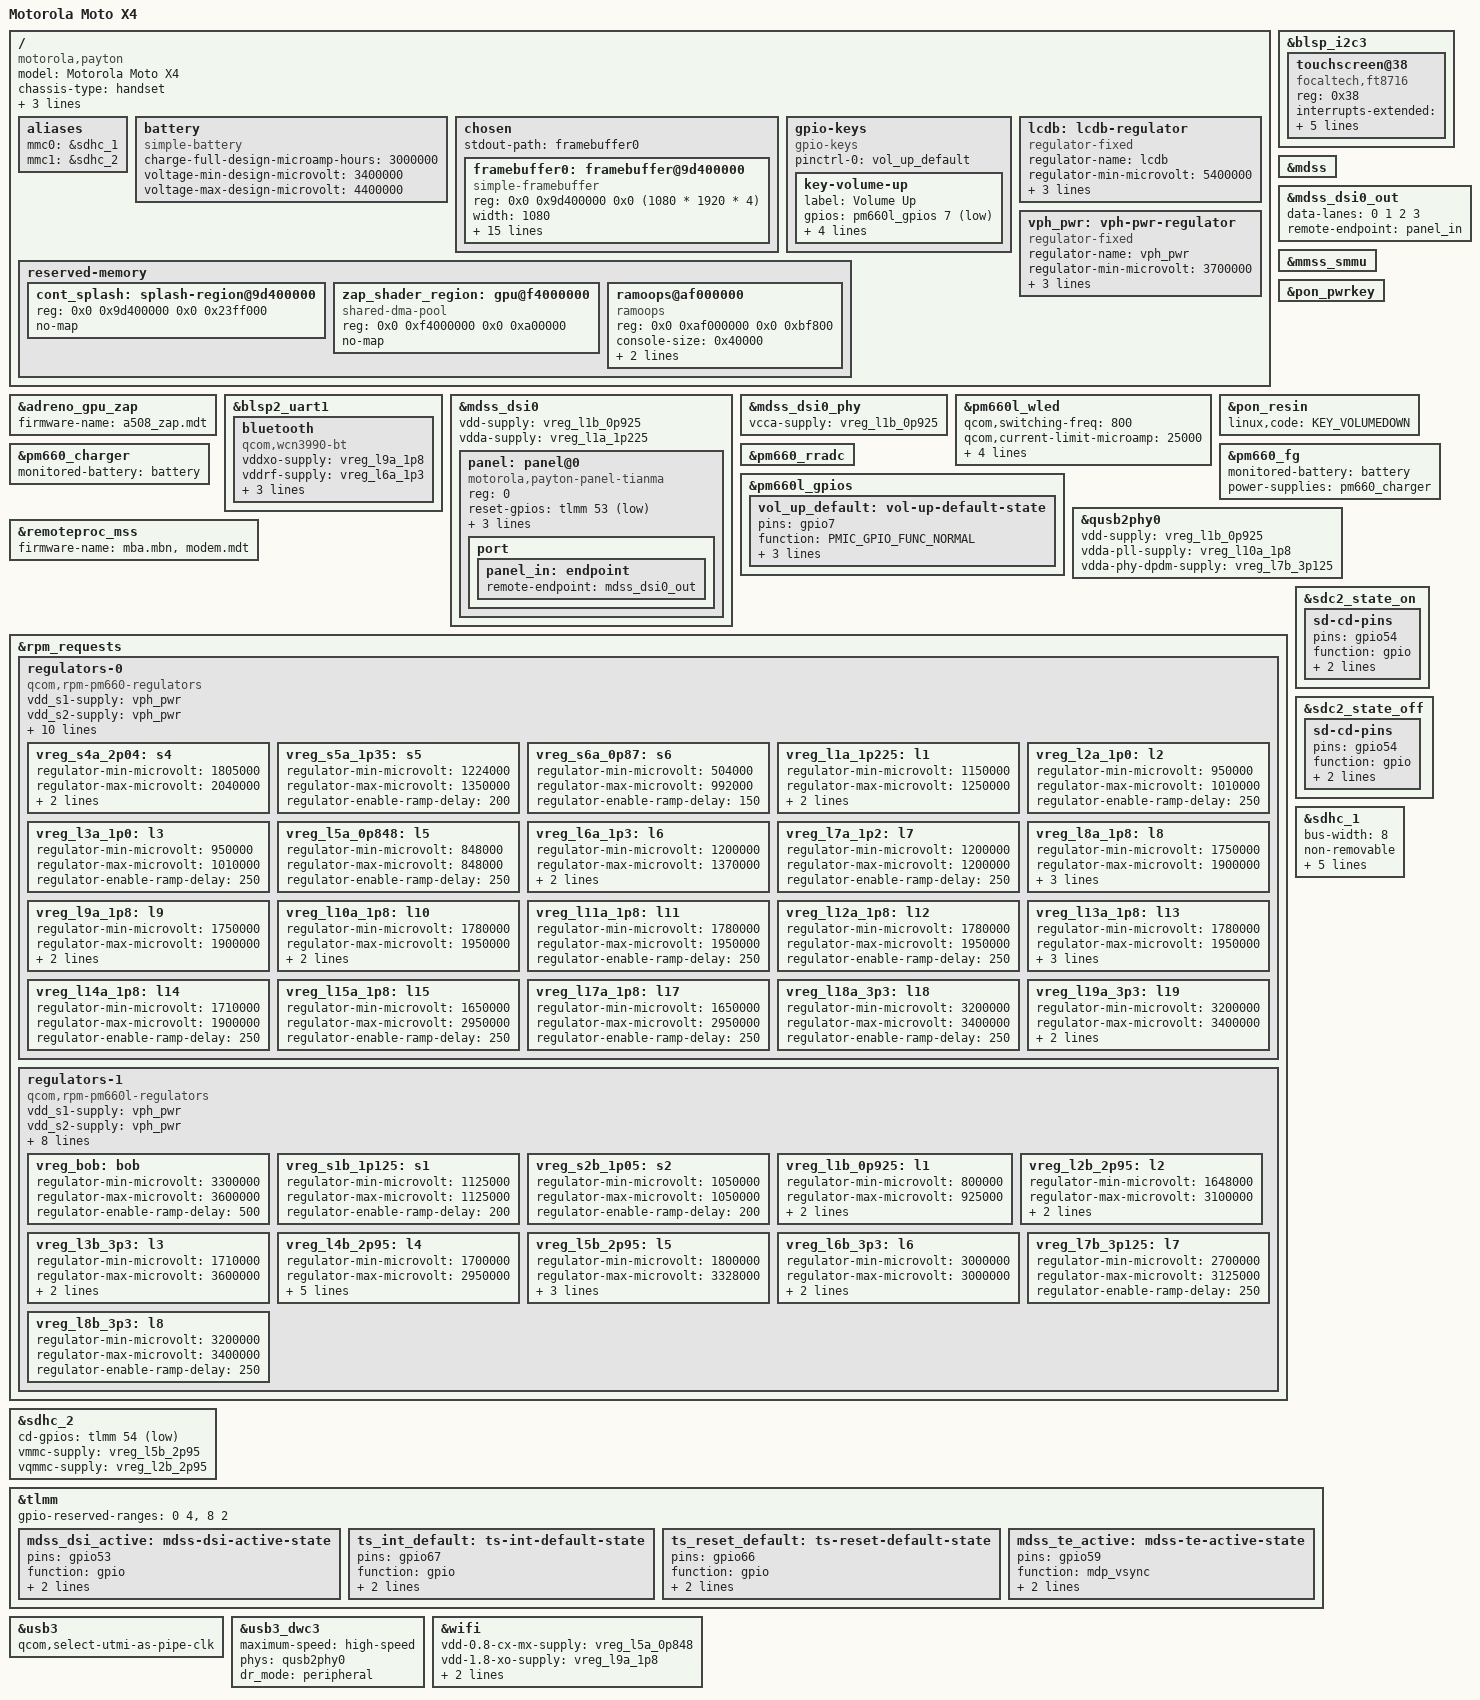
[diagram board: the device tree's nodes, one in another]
// SPDX-License-Identifier: GPL-2.0-only
/*
 * Motorola Moto X4 (payton)
 */

/dts-v1/;

#include "sdm630.dtsi"
#include "pm660.dtsi"
#include "pm660l.dtsi"
#include <dt-bindings/arm/qcom,ids.h>
#include <dt-bindings/input/input.h>
#include <dt-bindings/input/gpio-keys.h>
#include <dt-bindings/pinctrl/qcom,pmic-gpio.h>

/* The SoC default at 0xfed00000 lies past the end of payton's 3 GiB of RAM. */
/delete-node/ &zap_shader_region;

/ {
	model = "Motorola Moto X4";
	compatible = "motorola,payton", "qcom,sdm630";
	chassis-type = "handset";

	qcom,msm-id = <QCOM_ID_SDM630 0x0>;
	/* ABL picks the DTB by board-id; list every payton hardware revision. */
	qcom,board-id = <0x41 0x80a0>,
			<0x41 0x81a0>,
			<0x41 0x82a0>,
			<0x42 0x82a0>,
			<0x42 0x82b0>;

	/*
	 * eMMC as mmcblk0, like on the stock kernel: qbootctl only treats
	 * /dev/mmcblk0 as eMMC and otherwise wants a UFS boot-LUN switch.
	 */
	aliases {
		mmc0 = &sdhc_1;
		mmc1 = &sdhc_2;
		/delete-property/ mmc2;
	};

	battery: battery {
		compatible = "simple-battery";

		charge-full-design-microamp-hours = <3000000>;
		voltage-min-design-microvolt = <3400000>;
		voltage-max-design-microvolt = <4400000>;
	};

	chosen {
		#address-cells = <2>;
		#size-cells = <2>;
		ranges;

		stdout-path = "framebuffer0";

		framebuffer0: framebuffer@9d400000 {
			compatible = "simple-framebuffer";
			reg = <0x0 0x9d400000 0x0 (1080 * 1920 * 4)>;
			width = <1080>;
			height = <1920>;
			stride = <(1080 * 4)>;
			format = "a8r8g8b8";

			/* Keep the bootloader-enabled display path alive. */
			assigned-clocks = <&mmcc MDSS_MDP_CLK>, <&mmcc MDSS_VSYNC_CLK>;
			assigned-clock-rates = <300000000>, <19200000>;
			clocks = <&mmcc MDSS_AHB_CLK>,
				 <&mmcc MDSS_AXI_CLK>,
				 <&mmcc MDSS_VSYNC_CLK>,
				 <&mmcc MDSS_MDP_CLK>,
				 <&mmcc BYTE0_CLK_SRC>,
				 <&mmcc PCLK0_CLK_SRC>,
				 <&mmcc MDSS_BYTE0_CLK>,
				 <&mmcc MDSS_BYTE0_INTF_CLK>,
				 <&mmcc MNOC_AHB_CLK>,
				 <&mmcc MISC_AHB_CLK>,
				 <&mmcc MDSS_PCLK0_CLK>,
				 <&mmcc MDSS_ESC0_CLK>;
			power-domains = <&rpmpd SDM660_VDDCX>, <&mmcc MDSS_GDSC>;
		};
	};

	gpio-keys {
		compatible = "gpio-keys";

		pinctrl-0 = <&vol_up_default>;
		pinctrl-names = "default";

		key-volume-up {
			label = "Volume Up";
			gpios = <&pm660l_gpios 7 GPIO_ACTIVE_LOW>;
			linux,input-type = <EV_KEY>;
			linux,code = <KEY_VOLUMEUP>;
			wakeup-source;
			debounce-interval = <15>;
		};
	};

	/*
	 * PM660L LCDB powers the panel's positive and negative bias rails.
	 * There is no driver for it yet; the bootloader enables it (5.4 V).
	 */
	lcdb: lcdb-regulator {
		compatible = "regulator-fixed";
		regulator-name = "lcdb";
		regulator-min-microvolt = <5400000>;
		regulator-max-microvolt = <5400000>;
		regulator-always-on;
		regulator-boot-on;
	};

	reserved-memory {
		cont_splash: splash-region@9d400000 {
			reg = <0x0 0x9d400000 0x0 0x23ff000>;
			no-map;
		};

		zap_shader_region: gpu@f4000000 {
			compatible = "shared-dma-pool";
			reg = <0x0 0xf4000000 0x0 0xa00000>;
			no-map;
		};

		/*
		 * The stock kernel reserves 0xc0000 here but packs its single
		 * dmesg record at 0x3f800; the 0x800 smaller size gives the
		 * same zone offsets, so either kernel can read the other's log.
		 */
		ramoops@af000000 {
			compatible = "ramoops";
			reg = <0x0 0xaf000000 0x0 0xbf800>;
			console-size = <0x40000>;
			record-size = <0x3f800>;
			pmsg-size = <0x40000>;
		};
	};

	vph_pwr: vph-pwr-regulator {
		compatible = "regulator-fixed";
		regulator-name = "vph_pwr";
		regulator-min-microvolt = <3700000>;
		regulator-max-microvolt = <3700000>;

		regulator-always-on;
		regulator-boot-on;
	};
};

&adreno_gpu_zap {
	firmware-name = "a508_zap.mdt";
};

&blsp2_uart1 {
	status = "okay";

	bluetooth {
		compatible = "qcom,wcn3990-bt";
		vddxo-supply = <&vreg_l9a_1p8>;
		vddrf-supply = <&vreg_l6a_1p3>;
		vddch0-supply = <&vreg_l19a_3p3>;
		vddio-supply = <&vreg_l13a_1p8>;
		max-speed = <3200000>;
	};
};

&blsp_i2c3 {
	status = "okay";

	/* Touch part of the Tianma panel's FT8716 TDDI. */
	touchscreen@38 {
		compatible = "focaltech,ft8716";
		reg = <0x38>;

		interrupts-extended = <&tlmm 67 IRQ_TYPE_EDGE_FALLING>;
		reset-gpios = <&tlmm 66 GPIO_ACTIVE_LOW>;

		touchscreen-size-x = <1080>;
		touchscreen-size-y = <1920>;

		pinctrl-0 = <&ts_int_default &ts_reset_default>;
		pinctrl-names = "default";
	};
};

&mdss {
	status = "okay";
};

&mdss_dsi0 {
	vdd-supply = <&vreg_l1b_0p925>;
	vdda-supply = <&vreg_l1a_1p225>;

	status = "okay";

	panel: panel@0 {
		compatible = "motorola,payton-panel-tianma";
		reg = <0>;

		reset-gpios = <&tlmm 53 GPIO_ACTIVE_LOW>;
		vddio-supply = <&vreg_l11a_1p8>;
		backlight = <&pm660l_wled>;

		pinctrl-0 = <&mdss_dsi_active &mdss_te_active>;
		pinctrl-names = "default";

		port {
			panel_in: endpoint {
				remote-endpoint = <&mdss_dsi0_out>;
			};
		};
	};
};

&mdss_dsi0_out {
	data-lanes = <0 1 2 3>;
	remote-endpoint = <&panel_in>;
};

&mdss_dsi0_phy {
	vcca-supply = <&vreg_l1b_0p925>;

	status = "okay";
};

&mmss_smmu {
	status = "okay";
};

&pm660l_wled {
	qcom,switching-freq = <800>;
	qcom,current-limit-microamp = <25000>;
	qcom,current-boost-limit = <970>;
	qcom,ovp-millivolt = <18100>;
	qcom,num-strings = <3>;
	qcom,cabc;

	status = "okay";
};

&pon_pwrkey {
	status = "okay";
};

&pon_resin {
	linux,code = <KEY_VOLUMEDOWN>;

	status = "okay";
};

&pm660_charger {
	monitored-battery = <&battery>;

	status = "okay";
};

&pm660_fg {
	monitored-battery = <&battery>;
	power-supplies = <&pm660_charger>;

	status = "okay";
};

&pm660_rradc {
	status = "okay";
};

&pm660l_gpios {
	vol_up_default: vol-up-default-state {
		pins = "gpio7";
		function = PMIC_GPIO_FUNC_NORMAL;
		bias-pull-up;
		input-enable;
		qcom,drive-strength = <PMIC_GPIO_STRENGTH_NO>;
	};
};

&qusb2phy0 {
	vdd-supply = <&vreg_l1b_0p925>;
	vdda-pll-supply = <&vreg_l10a_1p8>;
	vdda-phy-dpdm-supply = <&vreg_l7b_3p125>;

	status = "okay";
};

&remoteproc_mss {
	firmware-name = "mba.mbn", "modem.mdt";

	status = "okay";
};

&rpm_requests {
	regulators-0 {
		compatible = "qcom,rpm-pm660-regulators";

		vdd_s1-supply = <&vph_pwr>;
		vdd_s2-supply = <&vph_pwr>;
		vdd_s3-supply = <&vph_pwr>;
		vdd_s4-supply = <&vph_pwr>;
		vdd_s5-supply = <&vph_pwr>;
		vdd_s6-supply = <&vph_pwr>;

		vdd_l1_l6_l7-supply = <&vreg_s5a_1p35>;
		vdd_l2_l3-supply = <&vreg_s2b_1p05>;
		vdd_l5-supply = <&vreg_s2b_1p05>;
		vdd_l8_l9_l10_l11_l12_l13_l14-supply = <&vreg_s4a_2p04>;
		vdd_l15_l16_l17_l18_l19-supply = <&vreg_bob>;

		/*
		 * S1A (FTAPC0), S2A (FTAPC1), S3A (HFAPC1) are managed
		 * by the Core Power Reduction hardened (CPRh) and the
		 * Operating State Manager (OSM) HW automatically.
		 */

		vreg_s4a_2p04: s4 {
			regulator-min-microvolt = <1805000>;
			regulator-max-microvolt = <2040000>;
			regulator-enable-ramp-delay = <200>;
			regulator-always-on;
		};

		vreg_s5a_1p35: s5 {
			regulator-min-microvolt = <1224000>;
			regulator-max-microvolt = <1350000>;
			regulator-enable-ramp-delay = <200>;
		};

		vreg_s6a_0p87: s6 {
			regulator-min-microvolt = <504000>;
			regulator-max-microvolt = <992000>;
			regulator-enable-ramp-delay = <150>;
		};

		vreg_l1a_1p225: l1 {
			regulator-min-microvolt = <1150000>;
			regulator-max-microvolt = <1250000>;
			regulator-enable-ramp-delay = <250>;
			regulator-allow-set-load;
		};

		vreg_l2a_1p0: l2 {
			regulator-min-microvolt = <950000>;
			regulator-max-microvolt = <1010000>;
			regulator-enable-ramp-delay = <250>;
		};

		vreg_l3a_1p0: l3 {
			regulator-min-microvolt = <950000>;
			regulator-max-microvolt = <1010000>;
			regulator-enable-ramp-delay = <250>;
		};

		/* WCN3990 CX/MX: fixed at 848 mV, as in the vendor kernel. */
		vreg_l5a_0p848: l5 {
			regulator-min-microvolt = <848000>;
			regulator-max-microvolt = <848000>;
			regulator-enable-ramp-delay = <250>;
		};

		vreg_l6a_1p3: l6 {
			regulator-min-microvolt = <1200000>;
			regulator-max-microvolt = <1370000>;
			regulator-allow-set-load;
			regulator-enable-ramp-delay = <250>;
		};

		vreg_l7a_1p2: l7 {
			regulator-min-microvolt = <1200000>;
			regulator-max-microvolt = <1200000>;
			regulator-enable-ramp-delay = <250>;
		};

		vreg_l8a_1p8: l8 {
			regulator-min-microvolt = <1750000>;
			regulator-max-microvolt = <1900000>;
			regulator-enable-ramp-delay = <250>;
			regulator-system-load = <325000>;
			regulator-allow-set-load;
		};

		vreg_l9a_1p8: l9 {
			regulator-min-microvolt = <1750000>;
			regulator-max-microvolt = <1900000>;
			regulator-enable-ramp-delay = <250>;
			regulator-allow-set-load;
		};

		vreg_l10a_1p8: l10 {
			regulator-min-microvolt = <1780000>;
			regulator-max-microvolt = <1950000>;
			regulator-enable-ramp-delay = <250>;
			regulator-allow-set-load;
		};

		vreg_l11a_1p8: l11 {
			regulator-min-microvolt = <1780000>;
			regulator-max-microvolt = <1950000>;
			regulator-enable-ramp-delay = <250>;
		};

		vreg_l12a_1p8: l12 {
			regulator-min-microvolt = <1780000>;
			regulator-max-microvolt = <1950000>;
			regulator-enable-ramp-delay = <250>;
		};

		/* Powers the LPDDR4: never turn it off. */
		vreg_l13a_1p8: l13 {
			regulator-min-microvolt = <1780000>;
			regulator-max-microvolt = <1950000>;
			regulator-enable-ramp-delay = <250>;
			regulator-boot-on;
			regulator-always-on;
		};

		vreg_l14a_1p8: l14 {
			regulator-min-microvolt = <1710000>;
			regulator-max-microvolt = <1900000>;
			regulator-enable-ramp-delay = <250>;
		};

		vreg_l15a_1p8: l15 {
			regulator-min-microvolt = <1650000>;
			regulator-max-microvolt = <2950000>;
			regulator-enable-ramp-delay = <250>;
		};

		vreg_l17a_1p8: l17 {
			regulator-min-microvolt = <1650000>;
			regulator-max-microvolt = <2950000>;
			regulator-enable-ramp-delay = <250>;
		};

		vreg_l18a_3p3: l18 {
			regulator-min-microvolt = <3200000>;
			regulator-max-microvolt = <3400000>;
			regulator-enable-ramp-delay = <250>;
		};

		vreg_l19a_3p3: l19 {
			regulator-min-microvolt = <3200000>;
			regulator-max-microvolt = <3400000>;
			regulator-enable-ramp-delay = <250>;
			regulator-allow-set-load;
		};
	};

	regulators-1 {
		compatible = "qcom,rpm-pm660l-regulators";

		vdd_s1-supply = <&vph_pwr>;
		vdd_s2-supply = <&vph_pwr>;
		vdd_s3_s4-supply = <&vph_pwr>;
		vdd_s5-supply = <&vph_pwr>;
		vdd_s6-supply = <&vph_pwr>;

		vdd_l1_l9_l10-supply = <&vreg_s2b_1p05>;
		vdd_l2-supply = <&vreg_bob>;
		vdd_l3_l5_l7_l8-supply = <&vreg_bob>;
		vdd_l4_l6-supply = <&vreg_bob>;
		vdd_bob-supply = <&vph_pwr>;

		vreg_bob: bob {
			regulator-min-microvolt = <3300000>;
			regulator-max-microvolt = <3600000>;
			regulator-enable-ramp-delay = <500>;
		};

		vreg_s1b_1p125: s1 {
			regulator-min-microvolt = <1125000>;
			regulator-max-microvolt = <1125000>;
			regulator-enable-ramp-delay = <200>;
		};

		vreg_s2b_1p05: s2 {
			regulator-min-microvolt = <1050000>;
			regulator-max-microvolt = <1050000>;
			regulator-enable-ramp-delay = <200>;
		};

		vreg_l1b_0p925: l1 {
			regulator-min-microvolt = <800000>;
			regulator-max-microvolt = <925000>;
			regulator-enable-ramp-delay = <250>;
			regulator-allow-set-load;
		};

		vreg_l2b_2p95: l2 {
			regulator-min-microvolt = <1648000>;
			regulator-max-microvolt = <3100000>;
			regulator-enable-ramp-delay = <250>;
			regulator-allow-set-load;
		};

		vreg_l3b_3p3: l3 {
			regulator-min-microvolt = <1710000>;
			regulator-max-microvolt = <3600000>;
			regulator-enable-ramp-delay = <250>;
			regulator-allow-set-load;
		};

		vreg_l4b_2p95: l4 {
			regulator-min-microvolt = <1700000>;
			regulator-max-microvolt = <2950000>;
			regulator-enable-ramp-delay = <250>;

			regulator-min-microamp = <200>;
			regulator-max-microamp = <600000>;
			regulator-system-load = <570000>;
			regulator-allow-set-load;
		};

		/* SDHCI2 VMMC requests a pinned 2.95V; keep the mmc core happy. */
		vreg_l5b_2p95: l5 {
			regulator-min-microvolt = <1800000>;
			regulator-max-microvolt = <3328000>;
			regulator-enable-ramp-delay = <250>;
			regulator-allow-set-load;
			regulator-system-load = <800000>;
		};

		vreg_l6b_3p3: l6 {
			regulator-min-microvolt = <3000000>;
			regulator-max-microvolt = <3000000>;
			regulator-enable-ramp-delay = <250>;
			regulator-ramp-delay = <0>;
		};

		vreg_l7b_3p125: l7 {
			regulator-min-microvolt = <2700000>;
			regulator-max-microvolt = <3125000>;
			regulator-enable-ramp-delay = <250>;
		};

		vreg_l8b_3p3: l8 {
			regulator-min-microvolt = <3200000>;
			regulator-max-microvolt = <3400000>;
			regulator-enable-ramp-delay = <250>;
		};
	};
};

&sdc2_state_on {
	sd-cd-pins {
		pins = "gpio54";
		function = "gpio";
		bias-pull-up;
		drive-strength = <2>;
	};
};

&sdc2_state_off {
	sd-cd-pins {
		pins = "gpio54";
		function = "gpio";
		bias-disable;
		drive-strength = <2>;
	};
};

&sdhc_1 {
	bus-width = <8>;
	non-removable;
	mmc-ddr-1_8v;
	mmc-hs200-1_8v;
	mmc-hs400-1_8v;
	vmmc-supply = <&vreg_l4b_2p95>;
	vqmmc-supply = <&vreg_l8a_1p8>;

	status = "okay";
};

&sdhc_2 {
	cd-gpios = <&tlmm 54 GPIO_ACTIVE_LOW>;
	vmmc-supply = <&vreg_l5b_2p95>;
	vqmmc-supply = <&vreg_l2b_2p95>;

	status = "okay";
};

&tlmm {
	/*
	 * 0-3: fingerprint SPI, owned by TZ. 8-9: reserved on other Moto
	 * SDM660 boards, and leaving them accessible made payton disappear
	 * entirely (likely a secure fault); 10-11 are blsp_i2c3.
	 */
	gpio-reserved-ranges = <0 4>, <8 2>;

	mdss_dsi_active: mdss-dsi-active-state {
		pins = "gpio53";
		function = "gpio";
		drive-strength = <8>;
		bias-disable;
	};

	ts_int_default: ts-int-default-state {
		pins = "gpio67";
		function = "gpio";
		drive-strength = <2>;
		bias-pull-up;
	};

	ts_reset_default: ts-reset-default-state {
		pins = "gpio66";
		function = "gpio";
		drive-strength = <2>;
		bias-disable;
	};

	mdss_te_active: mdss-te-active-state {
		pins = "gpio59";
		function = "mdp_vsync";
		drive-strength = <2>;
		bias-pull-down;
	};
};

&usb3 {
	qcom,select-utmi-as-pipe-clk;

	status = "okay";
};

&usb3_dwc3 {
	maximum-speed = "high-speed";
	phys = <&qusb2phy0>;
	phy-names = "usb2-phy";

	dr_mode = "peripheral";
};

&wifi {
	vdd-0.8-cx-mx-supply = <&vreg_l5a_0p848>;
	vdd-1.8-xo-supply = <&vreg_l9a_1p8>;
	vdd-1.3-rfa-supply = <&vreg_l6a_1p3>;
	vdd-3.3-ch0-supply = <&vreg_l19a_3p3>;

	status = "okay";
};
